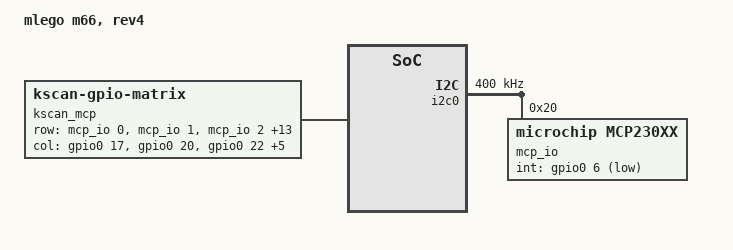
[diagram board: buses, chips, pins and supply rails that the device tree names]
#include "mlego_m66_rev4_layout.dtsi"

/ {
   model = "mlego m66, rev4";

   //compatible = "nice-nano-v2";

    m66_layout: m66_layout {
        compatible = "zmk,physical-layout";
        display-name = "m66 default layout";
        kscan = <&kscan_m66>;
   };

   chosen {
     zmk,physical-layout = &m66_layout;
     /* zephyr,console = &cdc_acm_uart; */
   };

  kscan_m66: kscan_composite {
    compatible = "zmk,kscan-composite";
    rows = <16>;
    columns = <8>;

    matrix {
      kscan = <&kscan_mcp>
    }
  };

  kscan_mcp: kscan_mcp {
    compatible = "zmk,kscan-gpio-matrix";
    diode-direction = "row2col";
    row-gpios = <&mcp_io 0 (GPIO_ACTIVE_HIGH | GPIO_PULL_UP)>,
                <&mcp_io 1 (GPIO_ACTIVE_HIGH | GPIO_PULL_UP)>,
                <&mcp_io 2 (GPIO_ACTIVE_HIGH | GPIO_PULL_UP)>,
                <&mcp_io 3 (GPIO_ACTIVE_HIGH | GPIO_PULL_UP)>,
                <&mcp_io 4 (GPIO_ACTIVE_HIGH | GPIO_PULL_UP)>,
                <&mcp_io 5 (GPIO_ACTIVE_HIGH | GPIO_PULL_UP)>,
                <&mcp_io 6 (GPIO_ACTIVE_HIGH | GPIO_PULL_UP)>,
                <&mcp_io 7 (GPIO_ACTIVE_HIGH | GPIO_PULL_UP)>,
                <&mcp_io 8 (GPIO_ACTIVE_HIGH | GPIO_PULL_UP)>,
                <&mcp_io 9 (GPIO_ACTIVE_HIGH | GPIO_PULL_UP)>,
                <&mcp_io 10 (GPIO_ACTIVE_HIGH | GPIO_PULL_UP)>,
                <&mcp_io 11 (GPIO_ACTIVE_HIGH | GPIO_PULL_UP)>,
                <&mcp_io 12 (GPIO_ACTIVE_HIGH | GPIO_PULL_UP)>,
                <&mcp_io 13 (GPIO_ACTIVE_HIGH | GPIO_PULL_UP)>,
                <&mcp_io 14 (GPIO_ACTIVE_HIGH | GPIO_PULL_UP)>,
                <&mcp_io 15 (GPIO_ACTIVE_HIGH | GPIO_PULL_UP)>;
    col-gpios = <&gpio0 17 (GPIO_ACTIVE_HIGH | GPIO_PULL_DOWN)>,
                <&gpio0 20 (GPIO_ACTIVE_HIGH | GPIO_PULL_DOWN)>,
                <&gpio0 22 (GPIO_ACTIVE_HIGH | GPIO_PULL_DOWN)>,
                <&gpio0 24 (GPIO_ACTIVE_HIGH | GPIO_PULL_DOWN)>,
                <&gpio1 0  (GPIO_ACTIVE_HIGH | GPIO_PULL_DOWN)>,
                <&gpio0 11 (GPIO_ACTIVE_HIGH | GPIO_PULL_DOWN)>,
                <&gpio1 4  (GPIO_ACTIVE_HIGH | GPIO_PULL_DOWN)>,
                <&gpio1 6  (GPIO_ACTIVE_HIGH | GPIO_PULL_DOWN)>;
  };
};

/* MCP23017 I²C GPIO expander */
&i2c0 {
  status = "okay";
  compatible = "nordic,nrf-twi";
  clock-frequency = <I2C_BITRATE_FAST>;
  /* 
  pinctrl-0 = <&i2c0_default>;
  pinctrl-1 = <&i2c0_sleep>;
  pinctrl-names = "default", "sleep";
  */

  mcp_io: mcp23017@20 {
    compatible = "microchip,mcp230xx";
    status = "okay";
    reg = <0x20>;
    gpio-controller;
    #gpio-cells = <2>;
    ngpios = <16>;
    int-gpios = <&gpio0 6 GPIO_ACTIVE_LOW>;  // 对应原理图中 INTA -> P0.06
  };
};

/*
&usbd {
    status = "okay";
    cdc_acm_uart: cdc_acm_uart {
        compatible = "zephyr,cdc-acm-uart";
    };
};
*/
